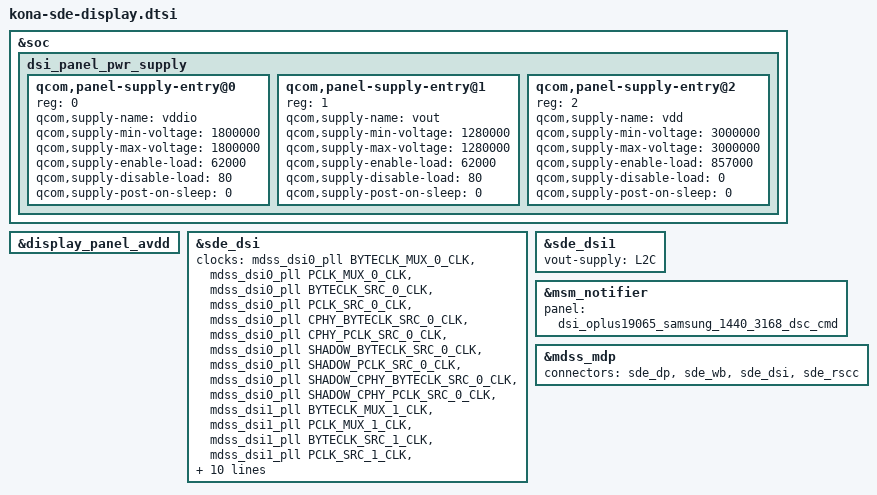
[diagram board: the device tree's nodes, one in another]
#include "dsi-panel-oplus19065-samsung-1440-3168-dsc-cmd.dtsi"
#include "pxlw/pxlw-iris5-cfg-oplus19065_samsung_1440_3168_cmd.dtsi"

&soc {
	dsi_panel_pwr_supply {
		/delete-node/ qcom,panel-supply-entry@3;

		qcom,panel-supply-entry@0 {
			reg = <0>;
			qcom,supply-name = "vddio";
			qcom,supply-min-voltage = <1800000>;
			qcom,supply-max-voltage = <1800000>;
			qcom,supply-enable-load = <62000>;
			qcom,supply-disable-load = <80>;
			qcom,supply-post-on-sleep = <0>;
		};

		qcom,panel-supply-entry@1 {
			reg = <1>;
			qcom,supply-name = "vout";
			qcom,supply-min-voltage = <1280000>;
			qcom,supply-max-voltage = <1280000>;
			qcom,supply-enable-load = <62000>;
			qcom,supply-disable-load = <80>;
			qcom,supply-post-on-sleep = <0>;
		};

		qcom,panel-supply-entry@2 {
			reg = <2>;
			qcom,supply-name = "vdd";
			qcom,supply-min-voltage = <3000000>;
			qcom,supply-max-voltage = <3000000>;
			qcom,supply-enable-load = <857000>;
			qcom,supply-disable-load = <0>;
			qcom,supply-post-on-sleep = <0>;
		};
	};
};

&display_panel_avdd {
	/delete-property/ gpio;
	/delete-property/ pinctrl-names;
	/delete-property/ pinctrl-0;
};

&sde_dsi {
	clocks = <&mdss_dsi0_pll BYTECLK_MUX_0_CLK>,
		 <&mdss_dsi0_pll PCLK_MUX_0_CLK>,
		 <&mdss_dsi0_pll BYTECLK_SRC_0_CLK>,
		 <&mdss_dsi0_pll PCLK_SRC_0_CLK>,
		 <&mdss_dsi0_pll CPHY_BYTECLK_SRC_0_CLK>,
		 <&mdss_dsi0_pll CPHY_PCLK_SRC_0_CLK>,
		 <&mdss_dsi0_pll SHADOW_BYTECLK_SRC_0_CLK>,
		 <&mdss_dsi0_pll SHADOW_PCLK_SRC_0_CLK>,
		 <&mdss_dsi0_pll SHADOW_CPHY_BYTECLK_SRC_0_CLK>,
		 <&mdss_dsi0_pll SHADOW_CPHY_PCLK_SRC_0_CLK>,
		 <&mdss_dsi1_pll BYTECLK_MUX_1_CLK>,
		 <&mdss_dsi1_pll PCLK_MUX_1_CLK>,
		 <&mdss_dsi1_pll BYTECLK_SRC_1_CLK>,
		 <&mdss_dsi1_pll PCLK_SRC_1_CLK>,
		 <&mdss_dsi1_pll CPHY_BYTECLK_SRC_1_CLK>,
		 <&mdss_dsi1_pll CPHY_PCLK_SRC_1_CLK>,
		 <&mdss_dsi1_pll SHADOW_BYTECLK_SRC_1_CLK>,
		 <&mdss_dsi1_pll SHADOW_PCLK_SRC_1_CLK>,
		 <&mdss_dsi1_pll SHADOW_CPHY_BYTECLK_SRC_1_CLK>,
		 <&mdss_dsi1_pll SHADOW_CPHY_PCLK_SRC_1_CLK>,
		 <&clock_rpmh RPMH_LN_BB_CLK2>;

	clock-names = "mux_byte_clk0", "mux_pixel_clk0",
			"src_byte_clk0", "src_pixel_clk0",
			"cphy_byte_clk0", "cphy_pixel_clk0",
			"shadow_byte_clk0", "shadow_pixel_clk0",
			"shadow_cphybyte_clk0", "shadow_cphypixel_clk0",
			"mux_byte_clk1", "mux_pixel_clk1",
			"src_byte_clk1", "src_pixel_clk1",
			"cphy_byte_clk1", "cphy_pixel_clk1",
			"shadow_byte_clk1", "shadow_pixel_clk1",
			"shadow_cphybyte_clk1", "shadow_cphypixel_clk1",
			"pw_bb_clk2";

	vout-supply = <&L2C>;

	qcom,dsi-default-panel = <&dsi_oplus19065_samsung_1440_3168_dsc_cmd>;
};

&sde_dsi1 {
	vout-supply = <&L2C>;
};

&msm_notifier {
	panel = <&dsi_oplus19065_samsung_1440_3168_dsc_cmd>;
};

&mdss_mdp {
	connectors = <&sde_dp &sde_wb &sde_dsi &sde_rscc>;
};

//#include "pxlw/pxlw-iris5.dtsi"
//#include "pxlw/dsi-panel-pxlw.dtsi"
